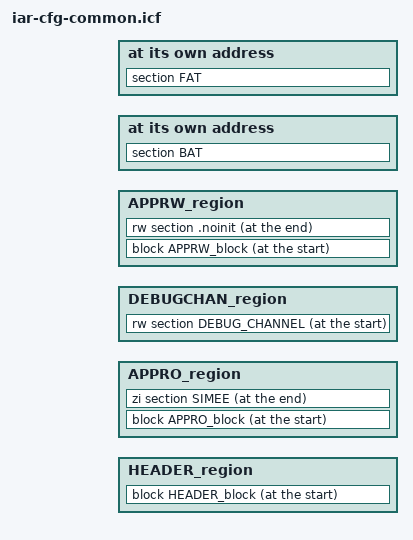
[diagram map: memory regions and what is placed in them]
// IAR V5 ILINK linker common configuration file.
//
// Copyright 2008-2009 by Ember Corporation. All rights reserved.           *80*
//=============================================================================

// This configuration file is common to all ember cortex chips.  It is
// included from a chip specific file which defines the following symbols:
//   RAM_BOTTOM
//   RAM_TOP
//   MFB_BOTTOM
//   MFB_TOP
//   CIB_BOTTOM
//   CIB_TOP
//   FIB_BOTTOM
//   FIB_TOP

//=============================================================================
// Flash placement.

// Basic memory layout of a NULL_BTL application in FLASH:
//  ---------------- MFB_TOP
//  | SIMEE        |
//  |--------------| MFB_TOP-0x2000 or MFB_TOP-0x1000
//  | Unused       |
//  |--------------| 0x080XXXXX
//  | DATA_INIT    |
//  |--------------| 0x080XXXXX
//  | CODE         |
//  |--------------| 0x08000184
//  | Vector Table | 
//  |--------------| 0x08000100
//  | Reserved     |
//  |--------------| 0x080000XX
//  | AAT          |
//  |--------------| 0x080000XX
//  | NULL BAT     |
//  |--------------| 0x08000000

// Basic memory layout of a bootloader application in FLASH:
//  ---------------- MFB_TOP
//  | SIMEE        |
//  |--------------| MFB_TOP-0x2000 or MFB_TOP-0x1000
//  | Unused       |
//  |--------------| 0x080XXXXX
//  | DATA_INIT    |
//  |--------------| 0x080XXXXX
//  | CONST        |
//  |--------------| 0x080XXXXX
//  | CODE         |
//  |--------------| 0x08000184 + BTL_SIZE
//  | Vector Table | 
//  |--------------| 0x08000100 + BTL_SIZE
//  | Reserved     |
//  |--------------| 0x080000XX + BTL_SIZE
//  | AAT          |
//  |--------------| 0x08000000 + BTL_SIZE   (== 0x08001000 or 0x08002000)
//  | Bootloader   |
//  |--------------| 0x080000XX
//  | BAT          |
//  |--------------| 0x08000000

// Determine the size of the bootloader
if( isdefinedsymbol(NULL_BTL) ) {
  define symbol BTL_SIZE = 0;
} else if( isdefinedsymbol(APP_BTL) || isdefinedsymbol(SERIAL_UART_BTL) ) {
  define symbol BTL_SIZE = 8K;
} else {
  // default to standalone bootloader
  define symbol BTL_SIZE = 8K;
}

//NOTE:  Simulated EEPROM size is determined by the sizing of the the
//       storage variable simulatedEepromStorage which is placed into
//       SIMEE section (which is placed at the end of the app).

// Define a Header region and associated block where the AAT will 
//  live (as well as a NULL BAT in the case of a NULL_BTL image)
define symbol HEADER_SIZE = 256;  // Must be multiple of 256 so the vector table
                                  // Can be placed immediately after the headers
define symbol HEADER_BOTTOM       = MFB_BOTTOM + BTL_SIZE;
define symbol HEADER_TOP          = HEADER_BOTTOM + (HEADER_SIZE-1);
define region HEADER_region       = mem:[from HEADER_BOTTOM to HEADER_TOP];
if( isdefinedsymbol(NULL_BTL) ) {
  // In the case of NULL_BTL, the dummy BAT gets placed at the beginning of
  //  all the headers
  define block HEADER_block with fixed order { ro section BAT, ro section AAT };
} else {
  // In other cases, the BAT is located at a fixed address in the bootloader, 
  //  and only the AAT occupies the HEADERS block
  define block HEADER_block with fixed order { ro section AAT };
  "BAT": place at address mem:MFB_BOTTOM { section BAT };
}
"HEADERS": place at start of HEADER_region { block HEADER_block };

// Define a region and block for containing the rest of the application RO sections
// The Application image lives in the flash remaining after the headers.
define symbol APPRO_BOTTOM          = HEADER_TOP + 1;
define symbol APPRO_TOP             = MFB_TOP;
define region APPRO_region          = mem:[from APPRO_BOTTOM to APPRO_TOP];
define block APPRO_block with fixed order { ro section .intvec, 
                                            ro section .textrw_init, 
                                            ro section .text, 
                                            ro section .rodata,
                                            ro section .data_init };
"APP ro": place at start of APPRO_region { block APPRO_block };
"SIMEE":  place at end of APPRO_region {zi section SIMEE};

// The FAT lives at a fixed address within the FIB
"FAT": place at address mem:FIB_BOTTOM { section FAT };

//=============================================================================
// RAM placement.

// Basic RAM layout
//  ---------------- RAM_TOP
//  | DEBUGCHANNEL |
//  |--------------| RAM_TOP - 0x00000020
//  | NOINIT       |
//  |--------------| 0x2000XXXX
//  | Unused       |
//  |--------------| 0x2000XXXX
//  | APP_RAM      |
//  |--------------| 0x2000XXXX
//  | TEXTRW       |
//  |--------------| 0x2000XXXX
//  | BSS          |
//  |--------------| 0x2000XXXX
//  | DATA         |
//  |--------------| 0x20000000 + STACK_SIZE  (Default 0x20000758)
//  | CSTACK       |
//  |   -   -   -  | 0x20000094
//  | RESETINFO    |   (Note: CSTACK extends down over RESETINFO when running)
//  |--------------| 0x20000000

// Define the call stack and reset info sections so that they overlay on top
// of each other.  The reset info is used to store reset/crash information and
// bootloader parameters across resets.  It is overlaid across the bottom of the
// call stack to avoid always dedicating RAM for this purpose even though it is
// only used just before and just after a software reset.
// These will be placed at the bottom of RAM so that a stack overflow will
// cause a memory fault and so the reset info can be found at a well
// known location.
define overlay CSTACK_overlay { rw section CSTACK };
define overlay CSTACK_overlay { rw section RESETINFO };

// Define a dedicated region for the debug channel which is a fixed size.
//  The size of ram available to the application will be reduced by this amount
define symbol DEBUGCHAN_SIZE    = 32;
define symbol DEBUGCHAN_BOTTOM  = RAM_TOP - (DEBUGCHAN_SIZE-1);
define symbol DEBUGCHAN_TOP     = RAM_TOP;
define region DEBUGCHAN_region  = mem:[from DEBUGCHAN_BOTTOM to DEBUGCHAN_TOP];
"DEBUGCHAN": place at start of DEBUGCHAN_region { rw section DEBUG_CHANNEL };

//Do not include the intializer tables or IAR init library code for any RW.
do not initialize { rw };
//But, .data and .textrw will be manually initialized so include init tables
// for them.
initialize manually { section .data, section .textrw };

// Define a region and block for containing the rest of the application RW sections
define symbol APPRW_BOTTOM      = RAM_BOTTOM;
define symbol APPRW_TOP         = DEBUGCHAN_BOTTOM - 1;
define region APPRW_region      = mem:[from APPRW_BOTTOM to APPRW_TOP];
define block APPRW_block with fixed order { overlay CSTACK_overlay, 
                                            rw section .textrw,
                                            rw section .data,
                                            rw section .bss,
                                            rw section APP_RAM };
"APP rw": place at start of APPRW_region { block APPRW_block };
"NOINIT": place at end of APPRW_region { rw section .noinit };

